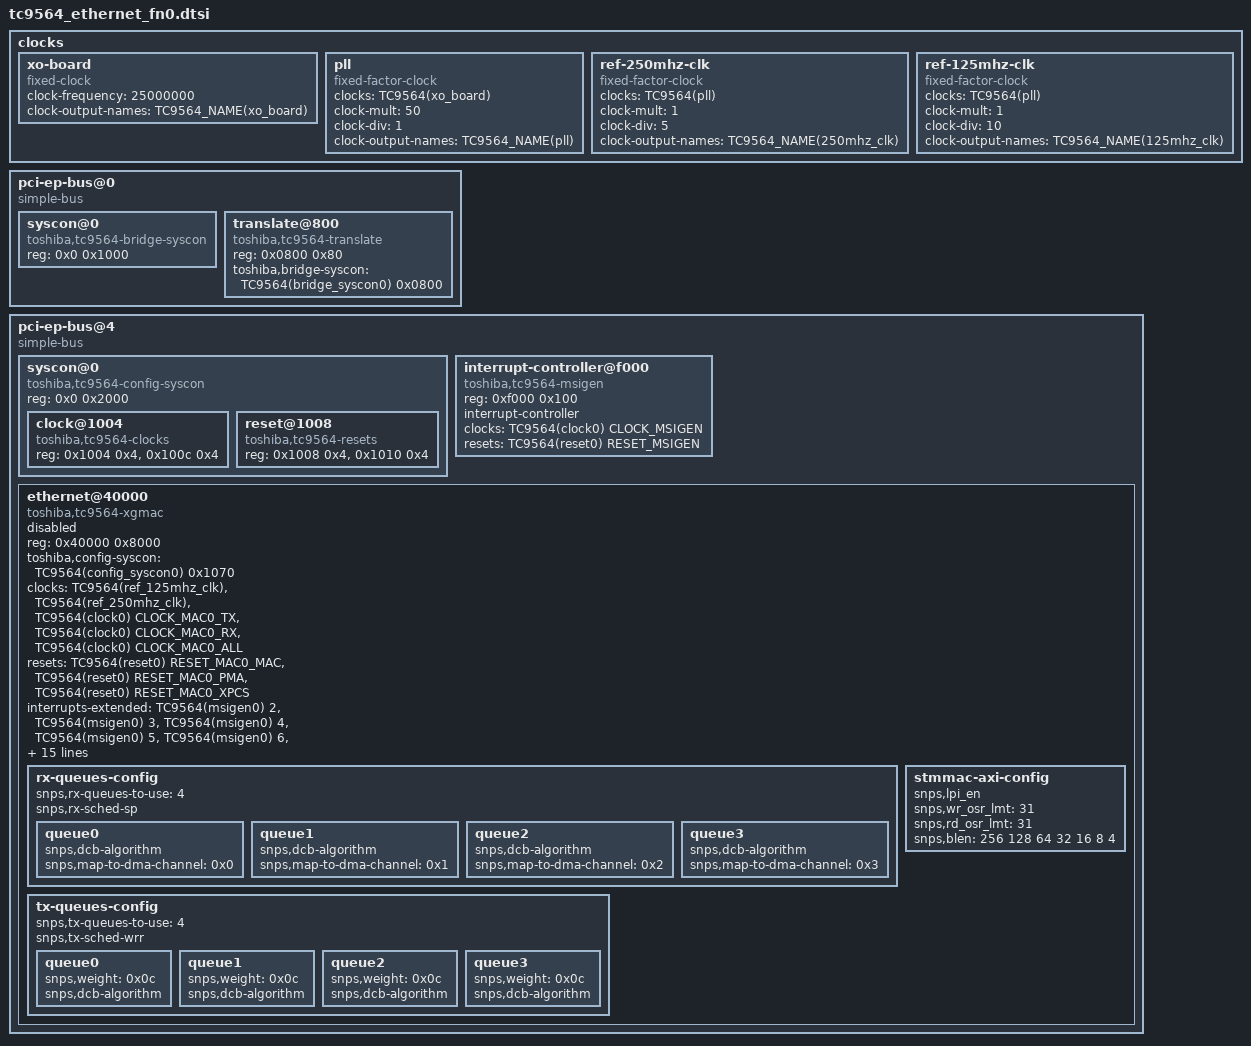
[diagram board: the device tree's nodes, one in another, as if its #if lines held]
// SPDX-License-Identifier: (GPL-2.0 OR MIT)

#include <dt-bindings/clock/toshiba,tc9564.h>
#include <dt-bindings/reset/toshiba,tc9564.h>

/*
 * TC9564_INSTANCE_NUMBER is needed to avoid symbol collisions when two
 * TC9564 instances are present in the same device tree. Ignore it otherwise!
 */
#ifdef TC9564_INSTANCE_NUMBER
#define TC9564(x) tc9564_##TC9564_INSTANCE_NUMBER##x
#else
#define TC9564(x) tc9564_##x
#endif

#define __stringify_1(x...) #x
#define __stringify(x...) __stringify_1(x)
#define TC9564_NAME(x) __stringify(TC9564(x))

clocks {
	TC9564(xo_board): xo-board {
		compatible = "fixed-clock";
		#clock-cells = <0>;
		clock-frequency = <25000000>;
		clock-output-names = TC9564_NAME(xo_board);
	};

	TC9564(pll): pll {
		compatible = "fixed-factor-clock";
		clocks = <&TC9564(xo_board)>;
		#clock-cells = <0>;
		clock-mult = <50>;
		clock-div = <1>;
		clock-output-names = TC9564_NAME(pll);
	};

	TC9564(ref_250mhz_clk): ref-250mhz-clk {
		compatible = "fixed-factor-clock";
		clocks = <&TC9564(pll)>;
		#clock-cells = <0>;
		clock-mult = <1>;
		clock-div = <5>;
		clock-output-names = TC9564_NAME(250mhz_clk);
	};

	TC9564(ref_125mhz_clk): ref-125mhz-clk {
		compatible = "fixed-factor-clock";
		clocks = <&TC9564(pll)>;
		#clock-cells = <0>;
		clock-mult = <1>;
		clock-div = <10>;
		clock-output-names = TC9564_NAME(125mhz_clk);
	};
};

pci-ep-bus@0 {
	compatible = "simple-bus";
	#address-cells = <1>;
	#size-cells = <1>;
	/* Map 0x0-0x3fff to BAR 0 */
	ranges = <0x0  0x0 0x0 0x0  0x4000>;

	TC9564(bridge_syscon0): syscon@0 {
		compatible = "toshiba,tc9564-bridge-syscon", "syscon";
		reg = <0x0 0x1000>;
	};

	TC9564(translate0): translate@800 {
		compatible = "toshiba,tc9564-translate";
		reg = <0x0800 0x80>;
		toshiba,bridge-syscon = <&TC9564(bridge_syscon0) 0x0800>;
	};
};

pci-ep-bus@4 {
	compatible = "simple-bus";
	#address-cells = <1>;
	#size-cells = <1>;
	/* Map 0x0-0x1fffff to BAR 4 */
	ranges = <0x0  0x4 0x0 0x0  0x200000>;

	TC9564(config_syscon0): syscon@0 {
		compatible = "toshiba,tc9564-config-syscon", "syscon", "simple-bus";
		reg = <0x0 0x2000>;

		#address-cells = <1>;
		#size-cells = <1>;
		ranges = <0x0 0x0 0x2000>;

		TC9564(clock0): clock@1004 {
			compatible = "toshiba,tc9564-clocks";
			reg = <0x1004 0x4>, <0x100c 0x4>;
			#clock-cells = <1>;
		};

		TC9564(reset0): reset@1008 {
			compatible = "toshiba,tc9564-resets";
			reg = <0x1008 0x4>, <0x1010 0x4>;
			#reset-cells = <1>;
		};
	};

	TC9564(msigen0): interrupt-controller@f000 {
		compatible = "toshiba,tc9564-msigen";
		reg = <0xf000 0x100>;

		interrupt-controller;
		#interrupt-cells = <1>;

		clocks = <&TC9564(clock0) CLOCK_MSIGEN>;
		clock-names = "toshiba,tc9564-msigen-clock";
		resets = <&TC9564(reset0) RESET_MSIGEN>;
		reset-names = "toshiba,tc9564-msigen-reset";
	};

	TC9564(emac0):ethernet@40000 {
		compatible = "toshiba,tc9564-xgmac";
		reg = <0x40000 0x8000>;
		status = "disabled";
		toshiba,config-syscon = <&TC9564(config_syscon0) 0x1070>;

		clocks = <&TC9564(ref_125mhz_clk)>,
			 <&TC9564(ref_250mhz_clk)>,
			 <&TC9564(clock0) CLOCK_MAC0_TX>,
			 <&TC9564(clock0) CLOCK_MAC0_RX>,
			 <&TC9564(clock0) CLOCK_MAC0_ALL>;
		clock-names = "stmmaceth",
			      "ptp_ref",
			      "mac-tx-clock",
			      "mac-rx-clock",
			      "mac-all-clock";

		resets = <&TC9564(reset0) RESET_MAC0_MAC>,
			 <&TC9564(reset0) RESET_MAC0_PMA>,
			 <&TC9564(reset0) RESET_MAC0_XPCS>;
		reset-names = "mac-reset",
			      "pma-reset",
		              "xpcs-reset";

		interrupts-extended = <&TC9564(msigen0) 2>,
				      <&TC9564(msigen0) 3>,
				      <&TC9564(msigen0) 4>,
				      <&TC9564(msigen0) 5>,
				      <&TC9564(msigen0) 6>,
				      <&TC9564(msigen0) 7>,
				      <&TC9564(msigen0) 8>,
				      <&TC9564(msigen0) 9>,
				      <&TC9564(msigen0) 10>,
				      <&TC9564(msigen0) 11>,
				      <&TC9564(msigen0) 12>,
				      <&TC9564(msigen0) 13>,
				      <&TC9564(msigen0) 14>,
				      <&TC9564(msigen0) 15>,
				      <&TC9564(msigen0) 16>,
				      <&TC9564(msigen0) 17>,
				      <&TC9564(msigen0) 18>;
		interrupt-names = "macirq",
			          "tx-queue-0",
			          "tx-queue-1",
			          "tx-queue-2",
			          "tx-queue-3",
			          "tx-queue-4",
			          "tx-queue-5",
			          "tx-queue-6",
			          "tx-queue-7",
			          "rx-queue-0",
			          "rx-queue-1",
			          "rx-queue-2",
			          "rx-queue-3",
			          "rx-queue-4",
			          "rx-queue-5",
			          "rx-queue-6",
			          "rx-queue-7";

		snps,tso;
		snps,pbl = <32>;
		snps,force_sf_dma_mode;
		snps,perfect-filter-entries = <32>;

		snps,mtl-rx-config = <&TC9564(mtl_rx_emac0_setup)>;
		snps,mtl-tx-config = <&TC9564(mtl_tx_emac0_setup)>;
		rx-fifo-depth = <32768>;
		tx-fifo-depth = <32768>;

		snps,axi-config = <&TC9564(axi_emac0_setup)>;

		TC9564(mtl_rx_emac0_setup): rx-queues-config {
			snps,rx-queues-to-use = <4>;
			snps,rx-sched-sp;
			queue0 {
				snps,dcb-algorithm;
				snps,map-to-dma-channel = <0x0>;
			};
			queue1 {
				snps,dcb-algorithm;
				snps,map-to-dma-channel = <0x1>;
			};
			queue2 {
				snps,dcb-algorithm;
				snps,map-to-dma-channel = <0x2>;
			};
			queue3 {
				snps,dcb-algorithm;
				snps,map-to-dma-channel = <0x3>;
			};
		};

		TC9564(mtl_tx_emac0_setup): tx-queues-config {
			snps,tx-queues-to-use = <4>;
			snps,tx-sched-wrr;
			queue0 {
				snps,weight = <0x0c>;
				snps,dcb-algorithm;
			};
			queue1 {
				snps,weight = <0x0c>;
				snps,dcb-algorithm;
			};
			queue2 {
				snps,weight = <0x0c>;
				snps,dcb-algorithm;
			};
			queue3 {
				snps,weight = <0x0c>;
				snps,dcb-algorithm;
			};
		};

		TC9564(axi_emac0_setup): stmmac-axi-config {
			snps,lpi_en;
			snps,wr_osr_lmt = <31>;
			snps,rd_osr_lmt = <31>;
			snps,blen = <256 128 64 32 16 8 4>;
		};
	};
};

#undef TC9564
